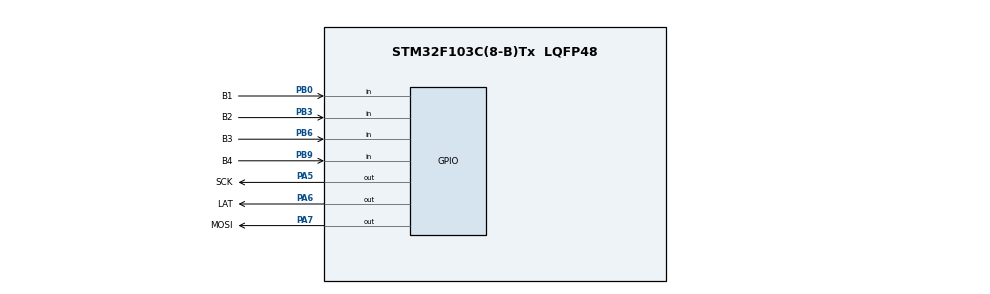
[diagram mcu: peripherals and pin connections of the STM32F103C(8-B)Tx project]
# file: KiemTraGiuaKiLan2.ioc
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Mcu.Family=STM32F1
Mcu.Name=STM32F103C(8-B)Tx
Mcu.Package=LQFP48
NVIC.PriorityGroup=NVIC_PRIORITYGROUP_4
PA13.Mode=Serial_Wire
PA13.Signal=SYS_JTMS-SWDIO
PA14.Mode=Serial_Wire
PA14.Signal=SYS_JTCK-SWCLK
PA5.GPIO_Label=SCK
PA5.Signal=GPIO_Output
PA6.GPIO_Label=LAT
PA6.Signal=GPIO_Output
PA7.GPIO_Label=MOSI
PA7.Signal=GPIO_Output
PB0.GPIO_Label=B1
PB0.GPIO_PuPd=GPIO_PULLUP
PB0.Signal=GPIO_Input
PB3.GPIO_Label=B2
PB3.GPIO_PuPd=GPIO_PULLUP
PB3.Signal=GPIO_Input
PB6.GPIO_Label=B3
PB6.GPIO_PuPd=GPIO_PULLUP
PB6.Signal=GPIO_Input
PB9.GPIO_Label=B4
PB9.GPIO_PuPd=GPIO_PULLUP
PB9.Signal=GPIO_Input
ProjectManager.HeapSize=0x200
ProjectManager.StackSize=0x400
ProjectManager.TargetToolchain=MDK-ARM V5.32
RCC.APB1Freq_Value=8000000
RCC.APB2Freq_Value=8000000
board=custom

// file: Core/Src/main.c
/* USER CODE BEGIN Header */
/**
  ******************************************************************************
  * @file           : main.c
  * @brief          : Main program body
  ******************************************************************************
  * @attention
  *
  * Copyright (c) 2024 STMicroelectronics.
  * All rights reserved.
  *
  * This software is licensed under terms that can be found in the LICENSE file
  * in the root directory of this software component.
  * If no LICENSE file comes with this software, it is provided AS-IS.
  *
  ******************************************************************************
  */
/* USER CODE END Header */
#include "main.h"

void SystemClock_Config(void);
static void MX_GPIO_Init(void);

void SCK()
{	HAL_GPIO_WritePin(SCK_GPIO_Port, SCK_Pin, GPIO_PIN_SET);
	HAL_GPIO_WritePin(SCK_GPIO_Port, SCK_Pin, GPIO_PIN_RESET);
}

void LAT()
{	HAL_GPIO_WritePin(LAT_GPIO_Port, LAT_Pin, GPIO_PIN_SET);
	HAL_GPIO_WritePin(LAT_GPIO_Port, LAT_Pin, GPIO_PIN_RESET);}

void tensv_74hc595_put(uint8_t ch)
{
	for (int i = 0; i < 8; i++)
	{
		HAL_GPIO_WritePin(MOSI_GPIO_Port, MOSI_Pin, ch & (1 << i));
		SCK();
	}
}

void tensv_LEDDecode(uint8_t num)
{
	uint8_t NUM[] = {0x3, 0x9F, 0x25, 0xD, 0x99, 0x49, 0x41, 0x1F, 0x1};
	for (int i = 0; i < 8; i++)
	{
		HAL_GPIO_WritePin(MOSI_GPIO_Port, MOSI_Pin, NUM[num] & (1 << i));
		SCK();
	}
	LAT();
}

void tensv_LED7seg_PutMatrix(uint8_t num[])
{
	for (int i = 8; i > -1 ; i--)
	{
		tensv_LEDDecode(num[i]);
	}
}

void tensv_LED7seg_PutNum(uint32_t num) {
    uint8_t array[8]; // Initialize array to hold 8 digits
    for (int i = 7; i >= 0; i--) {
        array[i] = num % 10;
        num /= 10;
    }
    tensv_LED7seg_PutMatrix(array);
}

uint8_t ReadButton() {
    uint8_t val = 0x00;
    uint8_t B1 = 0;
    uint8_t B2 = 0;
    uint8_t B3 = 0;
    uint8_t B4 = 0;

    // Read the state of each button
    B1 = HAL_GPIO_ReadPin(B1_GPIO_Port, B1_Pin);
    B2 = HAL_GPIO_ReadPin(B2_GPIO_Port, B2_Pin);
    B3 = HAL_GPIO_ReadPin(B3_GPIO_Port, B3_Pin);
    B4 = HAL_GPIO_ReadPin(B4_GPIO_Port, B4_Pin);

    // Combine the states into a single byte
    val |= (B1 << 0);
    val |= (B2 << 1);
    val |= (B3 << 2);
    val |= (B4 << 3);

    return val;
}

#define PRESS_ON GPIO_PIN_RESET
#define PRESS_OFF GPIO_PIN_RESET
#define B1 GPIO_PIN_RESET
#define B2 GPIO_PIN_RESET
#define B3 GPIO_PIN_RESET
#define B4 GPIO_PIN_RESET
#define COUNT_UP 1
#define COUNT_DOWN 2
uint8_t B1_state = 1, B2_state = 1, B3_state = 1, B4_state = 1 ;
uint8_t nMode = 0;
void StateM(void)
{
	uint8_t B1_vals = HAL_GPIO_ReadPin(B1_GPIO_Port, B1_Pin);
	uint8_t B2_vals = HAL_GPIO_ReadPin(B1_GPIO_Port, B2_Pin);
	uint8_t B3_vals = HAL_GPIO_ReadPin(B1_GPIO_Port, B3_Pin);
	uint8_t B4_vals = HAL_GPIO_ReadPin(B1_GPIO_Port, B4_Pin);

	uint8_t n = 0;

	if ((B1_state==1)&&(B1_vals==B1))
	{
		nMode = COUNT_UP;
		B1_state = 0;
	}
	else if ((B1_state==1)&&(B1_vals==!B1))
	{
		B1_state = 1;
	}

	if ((B2_state==1)&&(B2_vals==B2))
	{
		nMode = COUNT_UP;
		B1_state = 0;
	}
	else if ((B2_state==1)&&(B2_vals==!B2))
	{
		B1_state = 1;
	}

	if ((B3_state==1)&&(B3_vals==B3))
	{
		nMode = COUNT_DOWN;
		B3_state = 0;
	}
	else if ((B3_state==1)&&(B3_vals==!B3))
	{
		B3_state = 1;
	}

	if ((B4_state==1)&&(B4_vals==B4))
	{
		nMode = COUNT_UP;
		B4_state = 0;
	}
	else if ((B4_state==1)&&(B4_vals==!B4))
	{
		B4_state = 1;
	}

}

int main(void)
{

  /* MCU Configuration--------------------------------------------------------*/

  /* Reset of all peripherals, Initializes the Flash interface and the Systick. */
  HAL_Init();

  /* Configure the system clock */
  SystemClock_Config();

  /* Initialize all configured peripherals */
  MX_GPIO_Init();

  /* Infinite loop */
  /* USER CODE BEGIN WHILE */

	//

  while (1)
  {

    /* USER CODE END WHILE */

  }
}

void SystemClock_Config(void)
{
  RCC_OscInitTypeDef RCC_OscInitStruct = {0};
  RCC_ClkInitTypeDef RCC_ClkInitStruct = {0};

  /** Initializes the RCC Oscillators according to the specified parameters
  * in the RCC_OscInitTypeDef structure.
  */
  RCC_OscInitStruct.OscillatorType = RCC_OSCILLATORTYPE_HSI;
  RCC_OscInitStruct.HSIState = RCC_HSI_ON;
  RCC_OscInitStruct.HSICalibrationValue = RCC_HSICALIBRATION_DEFAULT;
  RCC_OscInitStruct.PLL.PLLState = RCC_PLL_NONE;
  if (HAL_RCC_OscConfig(&RCC_OscInitStruct) != HAL_OK)
  {
    Error_Handler();
  }

  /** Initializes the CPU, AHB and APB buses clocks
  */
  RCC_ClkInitStruct.ClockType = RCC_CLOCKTYPE_HCLK|RCC_CLOCKTYPE_SYSCLK
                              |RCC_CLOCKTYPE_PCLK1|RCC_CLOCKTYPE_PCLK2;
  RCC_ClkInitStruct.SYSCLKSource = RCC_SYSCLKSOURCE_HSI;
  RCC_ClkInitStruct.AHBCLKDivider = RCC_SYSCLK_DIV1;
  RCC_ClkInitStruct.APB1CLKDivider = RCC_HCLK_DIV1;
  RCC_ClkInitStruct.APB2CLKDivider = RCC_HCLK_DIV1;

  if (HAL_RCC_ClockConfig(&RCC_ClkInitStruct, FLASH_LATENCY_0) != HAL_OK)
  {
    Error_Handler();
  }
}

static void MX_GPIO_Init(void)
{
  GPIO_InitTypeDef GPIO_InitStruct = {0};

  /* GPIO Ports Clock Enable */
  __HAL_RCC_GPIOA_CLK_ENABLE();
  __HAL_RCC_GPIOB_CLK_ENABLE();

  /*Configure GPIO pin Output Level */
  HAL_GPIO_WritePin(GPIOA, SCK_Pin|LAT_Pin|MOSI_Pin, GPIO_PIN_RESET);

  /*Configure GPIO pins : SCK_Pin LAT_Pin MOSI_Pin */
  GPIO_InitStruct.Pin = SCK_Pin|LAT_Pin|MOSI_Pin;
  GPIO_InitStruct.Mode = GPIO_MODE_OUTPUT_PP;
  GPIO_InitStruct.Pull = GPIO_NOPULL;
  GPIO_InitStruct.Speed = GPIO_SPEED_FREQ_LOW;
  HAL_GPIO_Init(GPIOA, &GPIO_InitStruct);

  /*Configure GPIO pins : B1_Pin B2_Pin B3_Pin B4_Pin */
  GPIO_InitStruct.Pin = B1_Pin|B2_Pin|B3_Pin|B4_Pin;
  GPIO_InitStruct.Mode = GPIO_MODE_INPUT;
  GPIO_InitStruct.Pull = GPIO_PULLUP;
  HAL_GPIO_Init(GPIOB, &GPIO_InitStruct);

}

void Error_Handler(void)
{
  __disable_irq();
  while (1)
  {
  }
}
